# ATSAMA5D225CD1M device description
Architecture: CORTEX-A5; Family: SAMA5; Series: SAMA5D2
Registers are 32-bit, read-write, no defined reset value unless marked. A register's access mark holds for its fields unless they carry their own. Offsets are from the block's base; [hi:lo] are bit positions; lines under a group give offsets from that group; {n}, {i} and the like mark numbered series.

## MATRIX — AHB Bus Matrix
Instances: MATRIX0 0xF0018000, MATRIX1 0xFC03C000
{0x0+4i} MATRIX_MCFG[{i}] (i=0..11) — Master Configuration Register
  [2:0] ULBT — Undefined Length Burst Type
    0=UNLIMITED (Unlimited Length Burst-No predicted end of burst is generated, therefore INCR bursts coming from this master can only be broken if the Slave Slot Cycle Limit is reached. If the Slot Cycle Limit is not reached, the burst is normally completed by the master, at the latest, on the next AHB 1 Kbyte address boundary, allowing up to 256-beat word bursts or 128-beat double-word bursts.This value should not be used in the very particular case of a master capable of performing back-to-back undefined length bursts on a single slave, since this could indefinitely freeze the slave arbitration and thus prevent another master from accessing this slave.); 1=SINGLE (Single Access-The undefined length burst is treated as a succession of single accesses, allowing rearbitration at each beat of the INCR burst or bursts sequence.); 2=_4_BEAT (4-beat Burst-The undefined length burst or bursts sequence is split into 4-beat bursts or less, allowing rearbitration every 4 beats.); 3=_8_BEAT (8-beat Burst-The undefined length burst or bursts sequence is split into 8-beat bursts or less, allowing rearbitration every 8 beats.); 4=_16_BEAT (16-beat Burst-The undefined length burst or bursts sequence is split into 16-beat bursts or less, allowing rearbitration every 16 beats.); 5=_32_BEAT (32-beat Burst-The undefined length burst or bursts sequence is split into 32-beat bursts or less, allowing rearbitration every 32 beats.); 6=_64_BEAT (64-beat Burst-The undefined length burst or bursts sequence is split into 64-beat bursts or less, allowing rearbitration every 64 beats.); 7=_128_BEAT (128-beat Burst-The undefined length burst or bursts sequence is split into 128-beat bursts or less, allowing rearbitration every 128 beats.Unless duly needed, the ULBT should be left at its default 0 value for power saving.)
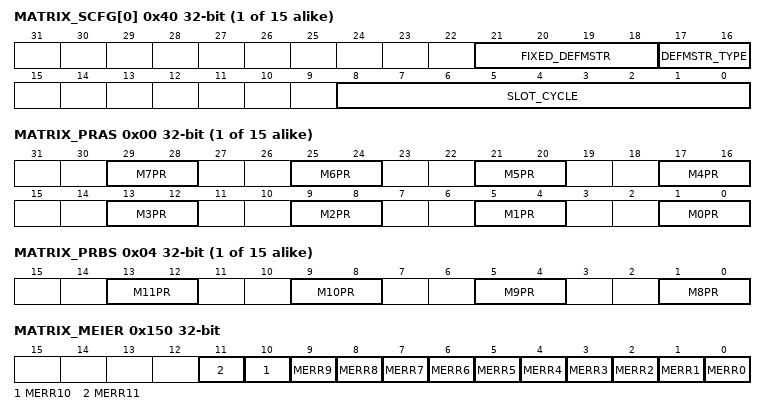
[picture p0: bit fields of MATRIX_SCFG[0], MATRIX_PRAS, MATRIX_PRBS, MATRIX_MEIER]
{0x40+4i} MATRIX_SCFG[{i}] (i=0..14) — Slave Configuration Register
  [21:18] FIXED_DEFMSTR — Fixed Default Master
  [17:16] DEFMSTR_TYPE — Default Master Type
    0=NONE (No Default Master-At the end of the current slave access, if no other master request is pending, the slave is disconnected from all masters.This results in a one clock cycle latency for the first access of a burst transfer or for a single access.); 1=LAST (Last Default Master-At the end of the current slave access, if no other master request is pending, the slave stays connected to the last master having accessed it.This results in not having one clock cycle latency when the last master tries to access the slave again.); 2=FIXED (Fixed Default Master-At the end of the current slave access, if no other master request is pending, the slave connects to the fixed master the number that has been written in the FIXED_DEFMSTR field.This results in not having one clock cycle latency when the fixed master tries to access the slave again.)
  [8:0] SLOT_CYCLE — Maximum Bus Grant Duration for Masters
{0x80+8i} MATRIX_PR[{i}] (i=0..14) group
  0x00 MATRIX_PRAS — Priority Register A for Slave 0
    [4n+1:4n] M{n}PR (n=0..7) — Master {n} Priority
  0x04 MATRIX_PRBS — Priority Register B for Slave 0
    [4n-31:4n-32] M{n}PR (n=8..11) — Master {n} Priority
0x150 MATRIX_MEIER wo — Master Error Interrupt Enable Register
  [n] MERR{n} (n=0..11) — Master {n} Access Error
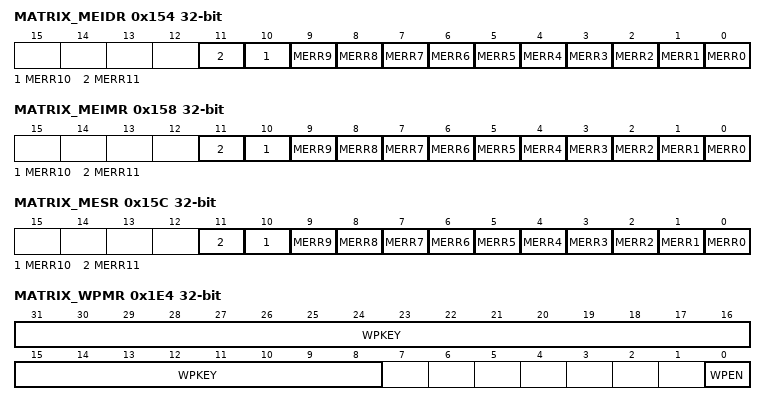
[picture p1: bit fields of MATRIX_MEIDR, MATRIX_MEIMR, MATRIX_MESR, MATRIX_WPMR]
0x154 MATRIX_MEIDR wo — Master Error Interrupt Disable Register
  [n] MERR{n} (n=0..11) — Master {n} Access Error
0x158 MATRIX_MEIMR ro — Master Error Interrupt Mask Register
  [n] MERR{n} (n=0..11) — Master {n} Access Error
0x15C MATRIX_MESR ro — Master Error Status Register
  [n] MERR{n} (n=0..11) — Master {n} Access Error
{0x160+4i} MATRIX_MEAR[{i}] (i=0..11) ro — Master 0 Error Address Register
  [31:0] ERRADD — Master Error Address
0x1E4 MATRIX_WPMR — Write Protection Mode Register
  [31:8] WPKEY — Write Protection Key (Write-only)
    0x4D4154=PASSWD (Writing any other value in this field aborts the write operation of the WPEN bit.Always reads as 0.)
  [0] WPEN — Write Protection Enable
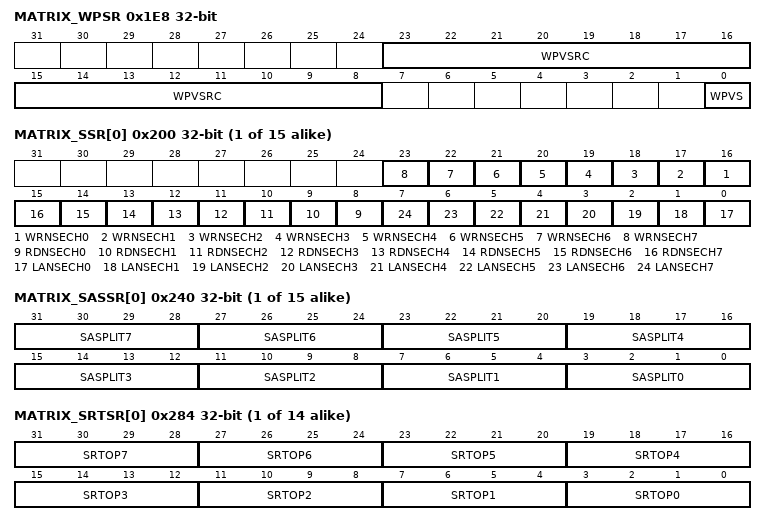
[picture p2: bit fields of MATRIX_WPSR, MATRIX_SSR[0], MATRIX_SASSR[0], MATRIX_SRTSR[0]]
0x1E8 MATRIX_WPSR ro — Write Protection Status Register
  [23:8] WPVSRC — Write Protection Violation Source
  [0] WPVS — Write Protection Violation Status
{0x200+4i} MATRIX_SSR[{i}] (i=0..14) — Security Slave 0 Register
  [n+16] WRNSECH{n} (n=0..7) — Write Non-secured for HSELx Security Region
  [n+8] RDNSECH{n} (n=0..7) — Read Non-secured for HSELx Security Region
  [n] LANSECH{n} (n=0..7) — Low Area Non-secured in HSELx Security Region
{0x240+4i} MATRIX_SASSR[{i}] (i=0..14) — Security Areas Split Slave 0 Register
  [4n+3:4n] SASPLIT{n} (n=0..7) — Security Areas Split for HSELx Security Region
{0x284+4i} MATRIX_SRTSR[{i}] (i=0..13) — Security Region Top Slave 1 Register
  [4n+3:4n] SRTOP{n} (n=0..7) — HSELx Security Region Top
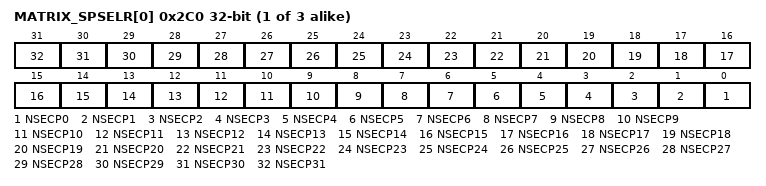
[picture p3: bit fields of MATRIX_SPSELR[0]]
{0x2C0+4i} MATRIX_SPSELR[{i}] (i=0..2) — Security Peripheral Select 1 Register
  [n] NSECP{n} (n=0..31) — Non-secured Peripheral
